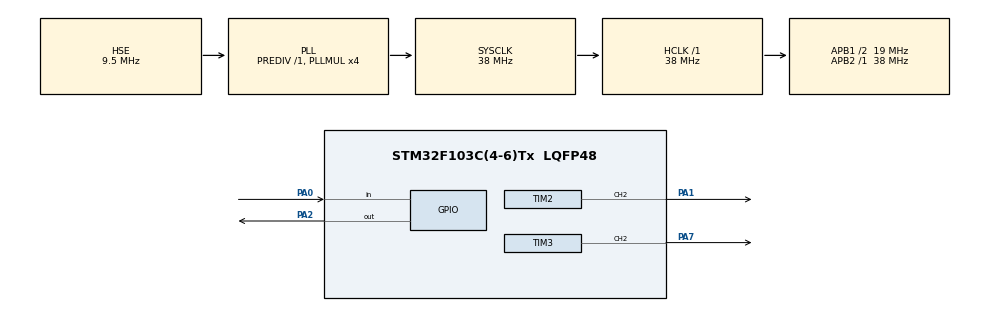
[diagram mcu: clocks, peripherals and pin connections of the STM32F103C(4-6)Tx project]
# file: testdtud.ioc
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Mcu.Family=STM32F1
Mcu.Name=STM32F103C(4-6)Tx
Mcu.Package=LQFP48
NVIC.PriorityGroup=NVIC_PRIORITYGROUP_4
NVIC.TIM3_IRQn=true\:3\:0\:true\:false\:true\:true\:true\:true
PA0-WKUP.Signal=GPIO_Input
PA1.Signal=S_TIM2_CH2
PA2.Signal=GPIO_Output
PA7.Signal=S_TIM3_CH2
PD0-OSC_IN.Mode=HSE-External-Oscillator
PD0-OSC_IN.Signal=RCC_OSC_IN
PD1-OSC_OUT.Mode=HSE-External-Oscillator
PD1-OSC_OUT.Signal=RCC_OSC_OUT
ProjectManager.HeapSize=0x200
ProjectManager.StackSize=0x400
ProjectManager.TargetToolchain=MDK-ARM V5.32
RCC.AHBFreq_Value=38000000
RCC.APB1CLKDivider=RCC_HCLK_DIV2
RCC.APB1Freq_Value=19000000
RCC.APB1TimFreq_Value=38000000
RCC.APB2Freq_Value=38000000
RCC.APB2TimFreq_Value=38000000
RCC.HCLKFreq_Value=38000000
RCC.HSE_VALUE=9500000
RCC.PLLMUL=RCC_PLL_MUL4
RCC.PLLSourceVirtual=RCC_PLLSOURCE_HSE
RCC.SYSCLKFreq_VALUE=38000000
RCC.SYSCLKSource=RCC_SYSCLKSOURCE_PLLCLK
RCC.USBFreq_Value=38000000
SH.S_TIM2_CH2.0=TIM2_CH2,PWM Generation2 CH2
SH.S_TIM3_CH2.0=TIM3_CH2,PWM Generation2 CH2
TIM1.Channel-PWM\ Generation2\ CH2=TIM_CHANNEL_2
TIM1.Period=0xFFFF
TIM1.Prescaler=37
TIM2.Channel-PWM\ Generation2\ CH2=TIM_CHANNEL_2
TIM2.Period=999
TIM2.Prescaler=0
TIM3.Channel-PWM\ Generation2\ CH2=TIM_CHANNEL_2
TIM3.Period=499
TIM3.Prescaler=3799
VP_SYS_VS_ND.Mode=No_Debug
VP_TIM1_VS_ClockSourceINT.Mode=Internal
VP_TIM2_VS_ClockSourceINT.Mode=Internal
VP_TIM3_VS_ClockSourceINT.Mode=Internal
board=custom

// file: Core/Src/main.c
/* USER CODE BEGIN Header */
/**
  ******************************************************************************
  * @file           : main.c
  * @brief          : Main program body
  ******************************************************************************
  * @attention
  *
  * Copyright (c) 2023 STMicroelectronics.
  * All rights reserved.
  *
  * This software is licensed under terms that can be found in the LICENSE file
  * in the root directory of this software component.
  * If no LICENSE file comes with this software, it is provided AS-IS.
  *
  ******************************************************************************
  */
/* USER CODE END Header */
#include "main.h"
int a,b,c;
/* USER CODE BEGIN Includes */
uint16_t d=0, e=0;
/* USER CODE END Includes */
	typedef enum {

	 b1=375,
	 b0=125,
	 bsync=250,
/** @endcond */
} bit;

TIM_HandleTypeDef htim1;
TIM_HandleTypeDef htim2;
TIM_HandleTypeDef htim3;

/* USER CODE BEGIN PV */
/*	void HAL_TIM_PWM_PulseFinishedCallback(TIM_HandleTypeDef *htim)
	{

			if(i<1425)
			{
				htim2.Instance->CCR2=500;

			}
		else if(i>1425&&i<1900)
			{
				htim2.Instance->CCR2=999;
			}
		else if(i>1900)
			{
				htim2.Instance->CCR2=500;
				i=0;

			}
		i++;
		HAL_TIM_PWM_Stop_IT(&htim2,TIM_CHANNEL_2);
	}*/
/**
/* USER CODE END PV */

void SystemClock_Config(void);
static void MX_GPIO_Init(void);
static void MX_TIM1_Init(void);
static void MX_TIM2_Init(void);
static void MX_TIM3_Init(void);

/* USER CODE BEGIN 0 */
void delay(uint32_t time)
	{
		__HAL_TIM_SetCounter(&htim1, 0);
	while(__HAL_TIM_GetCounter(&htim1)<time)
	{
	}
	}
	void bit_1(void)
	{
		htim3.Instance->CCR2=375;
	}
	void bit_0(void)
	{
		htim3.Instance->CCR2=125;
	}
	void bit_sync(void)
	{
		htim3.Instance->CCR2=250;
	}
		int read(void)
	{
		int e=0;
		uint16_t time=0;
		while(HAL_GPIO_ReadPin(GPIOA,GPIO_PIN_0)==1)
		{
			if(e==0)
			{
				time=HAL_GetTick();
				e=1;
			}
		}
		if(e==1)
			{
		time=HAL_GetTick()-time;
		if(time>10&&time<14)
			{	a++;
			}
		else if(time>=22&&time<=28)
			{
				b++;

			}
		else if(time>33&&time<=39)
			{	c++;

			}	}
	}
void HAL_TIM_PWM_PulseFinishedCallback(TIM_HandleTypeDef *htim)
	{
		d++;
		if(e==1)
		HAL_TIM_PWM_Stop_IT(&htim3,TIM_CHANNEL_2);

	}

/* USER CODE END 0 */

int main(void)
{

  /* MCU Configuration--------------------------------------------------------*/

  /* Reset of all peripherals, Initializes the Flash interface and the Systick. */
  HAL_Init();

  /* Configure the system clock */
  SystemClock_Config();

  /* Initialize all configured peripherals */
  MX_GPIO_Init();
  MX_TIM1_Init();
  MX_TIM2_Init();
  MX_TIM3_Init();
  /* USER CODE BEGIN 2 */
	HAL_TIM_Base_Start(&htim1);
	HAL_TIM_PWM_Start(&htim2,TIM_CHANNEL_2);
	htim2.Instance->CCR2=500;
	HAL_TIM_PWM_Start_IT(&htim3,TIM_CHANNEL_2);

  /* USER CODE END 2 */
	bit_0();

  /* Infinite loop */
  while (1)
  {
			read();
		if(d==1)
			{
				bit_1();
			}
		else if(d==2)
			{
				bit_0();
			}
		else if(d==3)
			{
				bit_1();
				d=0;
				e=1;
			}
  }
}

void SystemClock_Config(void)
{
  RCC_OscInitTypeDef RCC_OscInitStruct = {0};
  RCC_ClkInitTypeDef RCC_ClkInitStruct = {0};

  /** Initializes the RCC Oscillators according to the specified parameters
  * in the RCC_OscInitTypeDef structure.
  */
  RCC_OscInitStruct.OscillatorType = RCC_OSCILLATORTYPE_HSE;
  RCC_OscInitStruct.HSEState = RCC_HSE_ON;
  RCC_OscInitStruct.HSEPredivValue = RCC_HSE_PREDIV_DIV1;
  RCC_OscInitStruct.HSIState = RCC_HSI_ON;
  RCC_OscInitStruct.PLL.PLLState = RCC_PLL_ON;
  RCC_OscInitStruct.PLL.PLLSource = RCC_PLLSOURCE_HSE;
  RCC_OscInitStruct.PLL.PLLMUL = RCC_PLL_MUL4;
  if (HAL_RCC_OscConfig(&RCC_OscInitStruct) != HAL_OK)
  {
    Error_Handler();
  }

  /** Initializes the CPU, AHB and APB buses clocks
  */
  RCC_ClkInitStruct.ClockType = RCC_CLOCKTYPE_HCLK|RCC_CLOCKTYPE_SYSCLK
                              |RCC_CLOCKTYPE_PCLK1|RCC_CLOCKTYPE_PCLK2;
  RCC_ClkInitStruct.SYSCLKSource = RCC_SYSCLKSOURCE_PLLCLK;
  RCC_ClkInitStruct.AHBCLKDivider = RCC_SYSCLK_DIV1;
  RCC_ClkInitStruct.APB1CLKDivider = RCC_HCLK_DIV2;
  RCC_ClkInitStruct.APB2CLKDivider = RCC_HCLK_DIV1;

  if (HAL_RCC_ClockConfig(&RCC_ClkInitStruct, FLASH_LATENCY_1) != HAL_OK)
  {
    Error_Handler();
  }
}

static void MX_TIM1_Init(void)
{

  TIM_ClockConfigTypeDef sClockSourceConfig = {0};
  TIM_MasterConfigTypeDef sMasterConfig = {0};

  htim1.Instance = TIM1;
  htim1.Init.Prescaler = 37;
  htim1.Init.CounterMode = TIM_COUNTERMODE_UP;
  htim1.Init.Period = 0xFFFF;
  htim1.Init.ClockDivision = TIM_CLOCKDIVISION_DIV1;
  htim1.Init.RepetitionCounter = 0;
  htim1.Init.AutoReloadPreload = TIM_AUTORELOAD_PRELOAD_DISABLE;
  if (HAL_TIM_Base_Init(&htim1) != HAL_OK)
  {
    Error_Handler();
  }
  sClockSourceConfig.ClockSource = TIM_CLOCKSOURCE_INTERNAL;
  if (HAL_TIM_ConfigClockSource(&htim1, &sClockSourceConfig) != HAL_OK)
  {
    Error_Handler();
  }
  sMasterConfig.MasterOutputTrigger = TIM_TRGO_RESET;
  sMasterConfig.MasterSlaveMode = TIM_MASTERSLAVEMODE_DISABLE;
  if (HAL_TIMEx_MasterConfigSynchronization(&htim1, &sMasterConfig) != HAL_OK)
  {
    Error_Handler();
  }

}

static void MX_TIM2_Init(void)
{

  TIM_ClockConfigTypeDef sClockSourceConfig = {0};
  TIM_MasterConfigTypeDef sMasterConfig = {0};
  TIM_OC_InitTypeDef sConfigOC = {0};

  htim2.Instance = TIM2;
  htim2.Init.Prescaler = 0;
  htim2.Init.CounterMode = TIM_COUNTERMODE_UP;
  htim2.Init.Period = 999;
  htim2.Init.ClockDivision = TIM_CLOCKDIVISION_DIV1;
  htim2.Init.AutoReloadPreload = TIM_AUTORELOAD_PRELOAD_DISABLE;
  if (HAL_TIM_Base_Init(&htim2) != HAL_OK)
  {
    Error_Handler();
  }
  sClockSourceConfig.ClockSource = TIM_CLOCKSOURCE_INTERNAL;
  if (HAL_TIM_ConfigClockSource(&htim2, &sClockSourceConfig) != HAL_OK)
  {
    Error_Handler();
  }
  if (HAL_TIM_PWM_Init(&htim2) != HAL_OK)
  {
    Error_Handler();
  }
  sMasterConfig.MasterOutputTrigger = TIM_TRGO_RESET;
  sMasterConfig.MasterSlaveMode = TIM_MASTERSLAVEMODE_DISABLE;
  if (HAL_TIMEx_MasterConfigSynchronization(&htim2, &sMasterConfig) != HAL_OK)
  {
    Error_Handler();
  }
  sConfigOC.OCMode = TIM_OCMODE_PWM1;
  sConfigOC.Pulse = 0;
  sConfigOC.OCPolarity = TIM_OCPOLARITY_HIGH;
  sConfigOC.OCFastMode = TIM_OCFAST_DISABLE;
  if (HAL_TIM_PWM_ConfigChannel(&htim2, &sConfigOC, TIM_CHANNEL_2) != HAL_OK)
  {
    Error_Handler();
  }
  HAL_TIM_MspPostInit(&htim2);

}

static void MX_TIM3_Init(void)
{

  TIM_ClockConfigTypeDef sClockSourceConfig = {0};
  TIM_MasterConfigTypeDef sMasterConfig = {0};
  TIM_OC_InitTypeDef sConfigOC = {0};

  htim3.Instance = TIM3;
  htim3.Init.Prescaler = 3799;
  htim3.Init.CounterMode = TIM_COUNTERMODE_UP;
  htim3.Init.Period = 499;
  htim3.Init.ClockDivision = TIM_CLOCKDIVISION_DIV1;
  htim3.Init.AutoReloadPreload = TIM_AUTORELOAD_PRELOAD_DISABLE;
  if (HAL_TIM_Base_Init(&htim3) != HAL_OK)
  {
    Error_Handler();
  }
  sClockSourceConfig.ClockSource = TIM_CLOCKSOURCE_INTERNAL;
  if (HAL_TIM_ConfigClockSource(&htim3, &sClockSourceConfig) != HAL_OK)
  {
    Error_Handler();
  }
  if (HAL_TIM_PWM_Init(&htim3) != HAL_OK)
  {
    Error_Handler();
  }
  sMasterConfig.MasterOutputTrigger = TIM_TRGO_RESET;
  sMasterConfig.MasterSlaveMode = TIM_MASTERSLAVEMODE_DISABLE;
  if (HAL_TIMEx_MasterConfigSynchronization(&htim3, &sMasterConfig) != HAL_OK)
  {
    Error_Handler();
  }
  sConfigOC.OCMode = TIM_OCMODE_PWM1;
  sConfigOC.Pulse = 0;
  sConfigOC.OCPolarity = TIM_OCPOLARITY_HIGH;
  sConfigOC.OCFastMode = TIM_OCFAST_DISABLE;
  if (HAL_TIM_PWM_ConfigChannel(&htim3, &sConfigOC, TIM_CHANNEL_2) != HAL_OK)
  {
    Error_Handler();
  }
  HAL_TIM_MspPostInit(&htim3);

}

static void MX_GPIO_Init(void)
{
  GPIO_InitTypeDef GPIO_InitStruct = {0};

  /* GPIO Ports Clock Enable */
  __HAL_RCC_GPIOD_CLK_ENABLE();
  __HAL_RCC_GPIOA_CLK_ENABLE();

  /*Configure GPIO pin Output Level */
  HAL_GPIO_WritePin(GPIOA, GPIO_PIN_2, GPIO_PIN_RESET);

  /*Configure GPIO pin : PA0 */
  GPIO_InitStruct.Pin = GPIO_PIN_0;
  GPIO_InitStruct.Mode = GPIO_MODE_INPUT;
  GPIO_InitStruct.Pull = GPIO_NOPULL;
  HAL_GPIO_Init(GPIOA, &GPIO_InitStruct);

  /*Configure GPIO pin : PA2 */
  GPIO_InitStruct.Pin = GPIO_PIN_2;
  GPIO_InitStruct.Mode = GPIO_MODE_OUTPUT_PP;
  GPIO_InitStruct.Pull = GPIO_NOPULL;
  GPIO_InitStruct.Speed = GPIO_SPEED_FREQ_LOW;
  HAL_GPIO_Init(GPIOA, &GPIO_InitStruct);

}

void Error_Handler(void)
{
  __disable_irq();
  while (1)
  {
  }
}
